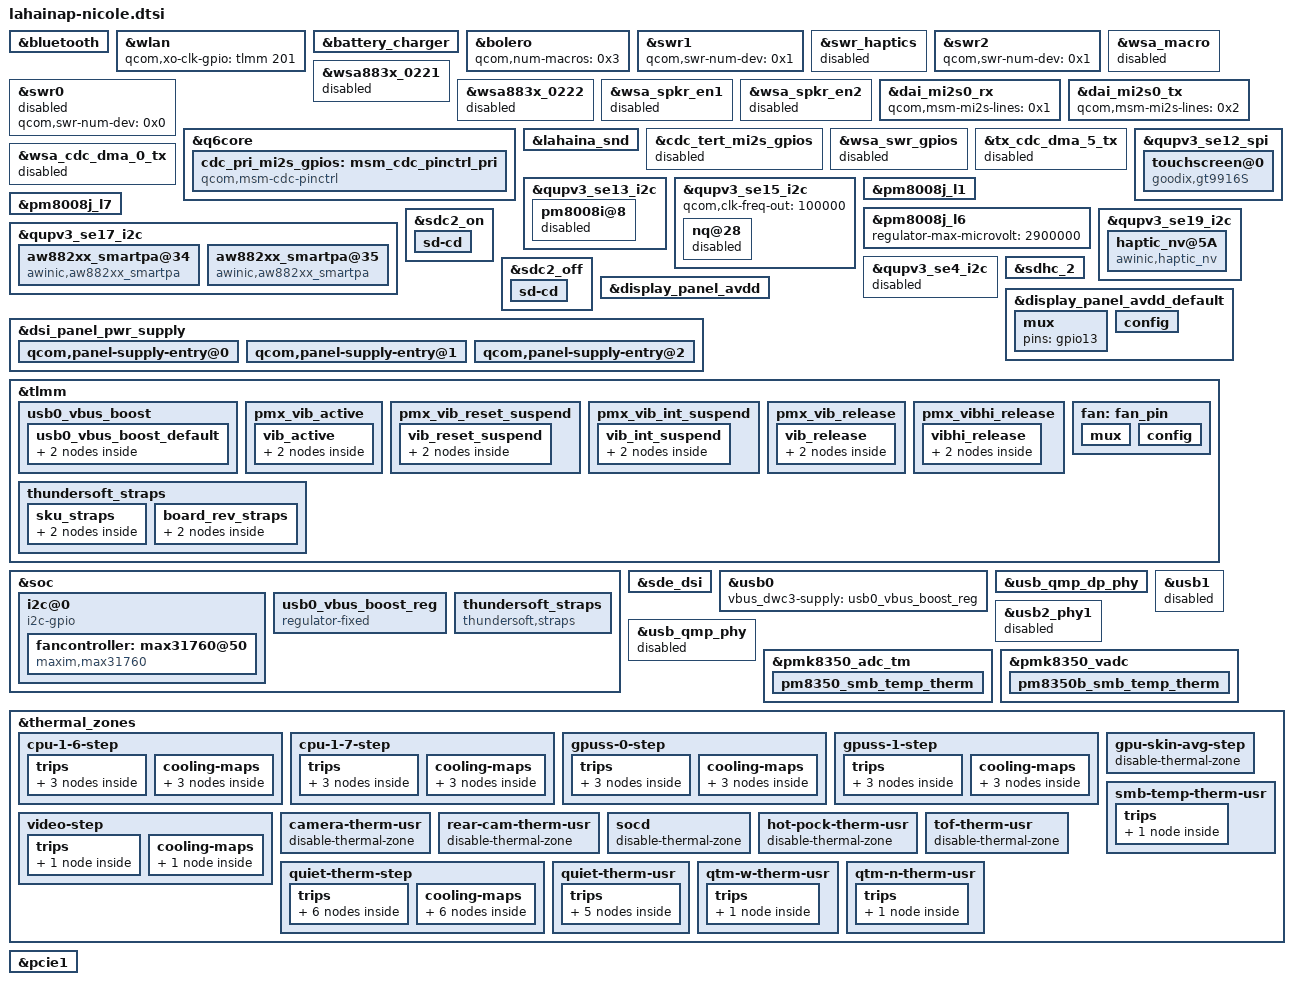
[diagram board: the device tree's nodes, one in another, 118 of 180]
#include <dt-bindings/clock/qcom,gcc-lahaina.h>
#include <dt-bindings/phy/qcom,usb3-5nm-qmp-combo.h>
#include "lahaina-qrd-common.dtsi"
#include "camera/lahaina-camera-sensor-nicole.dtsi"

&bluetooth {
	pinctrl-1 = <&wcnss_en_sleep>;
	qcom,xo-reset-gpio = <&tlmm 201 0>; /* XO */
};

&wlan {
	qcom,xo-clk-gpio = <&tlmm 201 0>;
};

&battery_charger {
	qcom,thermal-mitigation = <5000000 4000000 3000000 2000000 900000>;
};

&bolero {
	qcom,num-macros = <0x3>;
};

&swr1 {
	qcom,swr-num-dev = <0x1>;
};

&swr_haptics {
	status = "disabled";
};

&swr2 {
	qcom,swr-num-dev = <0x1>;
};

&wsa_macro {
	status = "disabled";
};

&swr0 {
	qcom,swr-num-dev = <0x0>;
	status = "disabled";
};

&wsa883x_0221 {
	status = "disabled";
};

&wsa883x_0222 {
	status = "disabled";
};

&wsa_spkr_en1 {
	status = "disabled";
};

&wsa_spkr_en2 {
	status = "disabled";
};

&dai_mi2s0_rx {
	qcom,msm-mi2s-lines = <0x1>;
};

&dai_mi2s0_tx {
	qcom,msm-mi2s-lines = <0x2>;
};

&q6core {
	cdc_pri_mi2s_gpios: msm_cdc_pinctrl_pri {
		compatible = "qcom,msm-cdc-pinctrl";
		pinctrl-names = "aud_active", "aud_sleep";
		pinctrl-0 = <&pri_mi2s_sck_active &pri_mi2s_ws_active
				&pri_mi2s_sd0_active &pri_mi2s_sd1_active>;
		pinctrl-1 = <&pri_mi2s_sck_sleep &pri_mi2s_ws_sleep
				&pri_mi2s_sd0_sleep &pri_mi2s_sd1_sleep>;
		#gpio-cells = <0>;
	};
};

&lahaina_snd {
	qcom,model = "lahaina-hhg-snd-card";

	qcom,audio-routing =
		"AMIC2", "Analog Mic2",
		"Analog Mic2", "MIC BIAS2",
		"TX DMIC1", "Digital Mic1",
		"Digital Mic1", "MIC BIAS1",
		"TX DMIC2", "Digital Mic2",
		"Digital Mic2", "MIC BIAS3",
		"IN1_HPHL", "HPHL_OUT",
		"IN2_HPHR", "HPHR_OUT",
		"IN3_AUX", "AUX_OUT",
		"RX_TX DEC0_INP", "TX DEC0 MUX",
		"RX_TX DEC1_INP", "TX DEC1 MUX",
		"RX_TX DEC2_INP", "TX DEC2 MUX",
		"RX_TX DEC3_INP", "TX DEC3 MUX",
		"TX SWR_INPUT", "WCD_TX_OUTPUT",
		"VA SWR_INPUT", "VA_SWR_CLK",
		"VA SWR_INPUT", "WCD_TX_OUTPUT",
		"VA_AIF1 CAP", "VA_SWR_CLK",
		"VA_AIF2 CAP", "VA_SWR_CLK",
		"VA_AIF3 CAP", "VA_SWR_CLK",
		"VA DMIC1", "Digital Mic1",
		"VA DMIC2", "Digital Mic2",
		"VA DMIC1", "VA MIC BIAS1",
		"VA DMIC2", "VA MIC BIAS2";
	qcom,msm-mbhc-usbc-audio-supported = <1>;
	qcom,msm-mbhc-hphl-swh = <0>;
	qcom,msm-mbhc-gnd-swh = <0>;
	qcom,mi2s-audio-intf = <1>;
	qcom,pri-mi2s-gpios = <&cdc_pri_mi2s_gpios>;
	/delete-property/ qcom,tert-mi2s-gpios;
	asoc-codec  = <&stub_codec>, <&bolero>,
		      <&wcd938x_codec>, <&swr_haptics>,
		      <&swr_dmic_04>, <&swr_dmic_03>,
		      <&swr_dmic_02>, <&swr_dmic_01>,
		      <&ext_disp_audio_codec>;
	asoc-codec-names = "msm-stub-codec.1", "bolero_codec",
			   "wcd938x_codec", "swr-haptics",
			   "swr-dmic.04", "swr-dmic.03",
			   "swr-dmic.02", "swr-dmic.01",
			   "msm-ext-disp-audio-codec-rx";
	qcom,wsa-max-devs = <0>;
};

&cdc_tert_mi2s_gpios {
	status = "disabled";
};

&wsa_swr_gpios {
	status = "disabled";
};

&tx_cdc_dma_5_tx {
	status = "disabled";
};

&wsa_cdc_dma_0_tx {
	status = "disabled";
};

&qupv3_se12_spi {
	status = "ok";

	touchscreen@0 {
		compatible = "goodix,gt9916S", "focaltech,fts";
		reg = <0x0>;
		spi-max-frequency = <6000000>;
		interrupt-parent = <&tlmm>;
		interrupts = <23 0x2008>;
		goodix,reset-gpio = <&tlmm 22 0x00>;
		goodix,irq-gpio = <&tlmm 23 0x2008>;
		goodix,irq-flags = <0x02>;
		goodix,max-touch-number = <5>;
		goodix,panel-max-x = <1080>;
		goodix,panel-max-y = <2400>;
		goodix,panel-max-w = <255>;
		goodix,panel-max-p = <4096>;
		goodix,firmware-name = "goodix_firmware.bin";
		goodix,config-name = "goodix_cfg_group.bin";
		goodix,pen-enable;
		focaltech,reset-gpio = <&tlmm 22 0x00>;
		focaltech,irq-gpio = <&tlmm 23 0x2008>;
		focaltech,max-touch-number = <10>;
		focaltech,display-coords = <0 0 1080 2400>;
		vdd-supply = <&L3C>;
		vcc_i2c-supply = <&L8C>;
		pinctrl-names = "pmx_ts_active", "pmx_ts_suspend", "pmx_ts_release";
		pinctrl-0 = <&ts_active>;
		pinctrl-1 = <&ts_int_suspend &ts_reset_suspend>;
		pinctrl-2 = <&ts_release>;
		panel = <&dsi_vtdr6130_amoled_cmd>;
	};
};

&qupv3_se13_i2c {
	pm8008i@8 {
		status = "disabled";
	};
};

&qupv3_se15_i2c {
	qcom,clk-freq-out = <100000>;
	nq@28 {
		status = "disabled";
	};
};

&pm8008j_l1 {
	regulator-max-microvolt = <1200000>;
	regulator-min-microvolt = <1200000>;
};

&pm8008j_l6 {
	regulator-max-microvolt = <2900000>;
};

&pm8008j_l7 {
	regulator-min-microvolt = <3200000>;
	regulator-max-microvolt = <3300000>;
};

&qupv3_se17_i2c {
	status = "ok";

	aw882xx_smartpa@34 {
		compatible = "awinic,aw882xx_smartpa";
		reg = <0x34>;
		irq-gpio = <&tlmm 90 0x2008>;
		dc-flag = <0>;
		monitor-flag = <1>;
		monitor-timer-val = <3000>;
		aw-tx-port-id = <0x1001>;
		aw-rx-port-id = <0x1000>;
		sound-channel = <0>;
		spin-mode = "dsp_spin";
		status = "okay";
	};

	aw882xx_smartpa@35 {
		compatible = "awinic,aw882xx_smartpa";
		reg = <0x35>;
		irq-gpio = <&tlmm 119 0x2008>;
		dc-flag = <0>;
		monitor-flag = <1>;
		monitor-timer-val = <3000>;
		aw-tx-port-id = <0x1001>;
		aw-rx-port-id = <0x1000>;
		sound-channel = <1>;
		spin-mode = "dsp_spin";
		status = "okay";
	};
};

&qupv3_se19_i2c {
	status = "ok";

	haptic_nv@5A {
		compatible = "awinic,haptic_nv";
		reg = <0x5A>;
		#cooling-cells = <0x2>;
		aw862xx_i2c_addr = <0x58>;
		interrupt-parent = <&tlmm>;
		interrupts = <44 0x2008>;
		reset-gpio = <&tlmm 106 0x0>;
		irq-gpio = <&tlmm 44 0x2008>;
		pinctrl-names = "pmx_vib_active", "pmx_vib_suspend", "pmx_vib_release", "pmx_vibhi_release";
		pinctrl-0 = <&vib_active &vibhi_release>;
		pinctrl-1 = <&vib_int_suspend &vib_reset_suspend>;
		pinctrl-2 = <&vib_release &vib_reset_suspend>;
		aw8622x_vib_lk_f0_cali = <0x0>;
		aw8622x_vib_mode = <0x2>;
		aw8622x_vib_f0_pre = <0x92E>;
		aw8622x_vib_f0_cali_percen = <0x7>;
		aw8622x_vib_cont_drv1_lvl = <0x7F>;
		aw8622x_vib_cont_drv2_lvl = <0x4E>;
		aw8622x_vib_cont_brk_time = <0x6>;
		aw8622x_vib_cont_tset = <0x6>;
		aw8622x_vib_cont_bemf_set = <0x2>;
		aw8622x_vib_cont_drv_width = <0x44>;
		aw8622x_vib_cont_wait_num = <0x6>;
		aw8622x_vib_cont_brk_gain = <0x8>;
		aw8622x_vib_cont_drv1_time = <0x4>;
		aw8622x_vib_cont_drv2_time = <0x14>;
		aw8622x_vib_cont_track_margin = <0x12>;
		aw8622x_vib_sine_array = <0x5 0xB2 0xFF 0xEF>;
		aw8622x_vib_d2s_gain = <0x6>;
		aw8622x_vib_trig_config = <0x0 0x0 0x0 0x1 0x0 0x2 0x0 0x0 0x0 0x0 0x1 0x0 0x2 0x0 0x0 0x0 0x0 0x1 0x0 0x2 0x0>;
		aw8622x_vib_duration_time = <0x14 0x1E 0x3C>;
		status = "okay";
	};
};

&qupv3_se4_i2c {
	status = "disabled";

	/delete-node/ focaltech@38;
};

&sdc2_on {
	sd-cd {
		pins = "gpio80";
		bias-pull-up;
		drive-strength = <2>;
	};
};

&sdc2_off {
	sd-cd {
		pins = "gpio80";
		bias-disable;
		drive-strength = <2>;
	};
};

&sdhc_2 {
	cd-gpios = <&tlmm 80 GPIO_ACTIVE_HIGH>;

	cap-mmc-hw-reset;

	resets = <&clock_gcc GCC_SDCC2_BCR>;
	reset-names = "core_reset";
};

&display_panel_avdd {
	/delete-property/ enable-active-high;
	enable-active-low;
	gpio = <&tlmm 13 0>;
};

&dsi_panel_pwr_supply {
	qcom,panel-supply-entry@0 {
		qcom,supply-min-voltage = <1860000>;
		qcom,supply-max-voltage = <1860000>;
	};

	qcom,panel-supply-entry@1 {
		qcom,supply-pre-off-sleep = <2>;
		qcom,supply-post-off-sleep = <2>;
	};

	qcom,panel-supply-entry@2 {
		qcom,supply-name = "avdd";
		qcom,supply-enable-load = <100000>;
	};

	/delete-node/ qcom,panel-supply-entry@3;
};

&display_panel_avdd_default {
	mux {
		pins = "gpio13";
	};

	config {
		pins = "gpio13";
		/delete-property/ output-high;
		output-low;
	};
};

&tlmm {
	usb0_vbus_boost {
		usb0_vbus_boost_default: usb0_vbus_boost_default {
			mux {
				pins = "gpio79";
				function = "gpio";
			};

			config {
				pins = "gpio79";
				bias-pull-up;
				drive-strength = <6>;
				input-enable;
			};
		};
	};

	pmx_vib_active {
		vib_active: vib_active {
			mux {
				pins = "gpio106", "gpio44";
				function = "gpio";
			};

			config {
				pins = "gpio106", "gpio44";
				drive-strength = <8>;
				bias-pull-up;
			};
		};
	};

	pmx_vib_reset_suspend {
		vib_reset_suspend: vib_reset_suspend {
			mux {
				pins = "gpio106";
				function = "gpio";
			};

			config {
				pins = "gpio106";
				drive-strength = <2>;
				bias-pull-down;
			};
		};
	};

	pmx_vib_int_suspend {
		vib_int_suspend: vib_int_suspend {
			mux {
				pins = "gpio44";
				function = "gpio";
			};

			config {
				pins = "gpio44";
				drive-strength = <2>;
				bias-pull-down;
			};
		};
	};

	pmx_vib_release {
		vib_release: vib_release {
			mux {
				pins = "gpio106", "gpio44";
				function = "gpio";
			};

			config {
				pins = "gpio106", "gpio44";
				drive-strength = <2>;
				bias-disable;
			};
		};
	};

	pmx_vibhi_release {
		vibhi_release: vibhi_release {
			mux {
				pins = "gpio16", "gpio17";
				function = "gpio";
			};

			config {
				pins = "gpio16", "gpio17";
				bias-high-impedance;
			};
		};
	};

	fan: fan_pin {
		mux {
			pins = "gpio8", "gpio9";
			function = "gpio";
		};

		config {
			pins = "gpio8", "gpio9";
			bias-pull-up;
			drive-strength = <16>;
		};
	};

	thundersoft_straps {
		sku_straps: sku_straps {
			mux {
				pins = "gpio3", "gpio6", "gpio7";
				function = "gpio";
			};

			config {
				pins = "gpio3", "gpio6", "gpio7";
				drive-strength = <2>;
				bias-pull-up;
				input-enable;
			};
		};

		board_rev_straps: board_rev_straps {
			mux {
				pins = "gpio45", "gpio50", "gpio51";
				function = "gpio";
			};

			config {
				pins = "gpio45", "gpio50", "gpio51";
				drive-strength = <2>;
				bias-pull-up;
				input-enable;
			};
		};
	};
};

&soc {
	i2c@0 {
		compatible = "i2c-gpio";
		reg = <0x0>;
		pinctrl-names = "default";
		pinctrl-0 = <&fan>;
		gpios = <&tlmm 8 (GPIO_ACTIVE_HIGH | GPIO_OPEN_DRAIN) /* sda */>,
			<&tlmm 9 (GPIO_ACTIVE_HIGH | GPIO_OPEN_DRAIN) /* scl */>;

		i2c-gpio,sda-open-drain;
		i2c-gpio,scl-open-drain;
		i2c-gpio,delay-us = <5>;
		#address-cells = <1>;
		#size-cells = <0>;

		fancontroller: max31760@50 {
			compatible = "maxim,max31760";
			reg = <0x50>;
			#cooling-cells = <2>;
			maxim,vdd-supply = <&pm8008j_l7>;
			regulator-names = "maxim,vdd";
			maxim,vdda-supply = <&pm8008j_l6>;
			maxim,vcca-supply = <&pm8350_s10>;
			maxim,usb_charge_contrl = <&tlmm 78 0>;
			maxim,dpr_contrl = <&tlmm 93 0>;
			pinctrl-names = "qupv3_se19_spi_pins";
			pinctrl-1 = <&qupv3_se19_spi_sleep>;
			status = "ok";
		};
	};

	usb0_vbus_boost_reg: usb0_vbus_boost_reg {
		compatible = "regulator-fixed";
		regulator-name = "usb0_vbus_boost_reg";
		regulator-min-microvolt = <5000000>;
		regulator-max-microvolt = <5000000>;
		enable-active-high;
		gpio = <&tlmm 48 GPIO_ACTIVE_HIGH>;
		interrupt-parent = <&tlmm>;
		interrupts = <79 0x2008>;
		interrupt-names = "ocp";
		pinctrl-names = "default";
		pinctrl-0 = <&usb0_vbus_boost_default>;
	};

	thundersoft_straps {
		compatible = "thundersoft,straps";
		sku-gpios = <&tlmm 3 (GPIO_ACTIVE_HIGH | GPIO_PULL_UP)>,
			<&tlmm 6 (GPIO_ACTIVE_HIGH | GPIO_PULL_UP)>,
			<&tlmm 7 (GPIO_ACTIVE_HIGH | GPIO_PULL_UP)>;
		board_rev-gpios = <&tlmm 45 (GPIO_ACTIVE_HIGH | GPIO_PULL_UP)>,
			<&tlmm 50 (GPIO_ACTIVE_HIGH | GPIO_PULL_UP)>,
			<&tlmm 51 (GPIO_ACTIVE_HIGH | GPIO_PULL_UP)>;
		pinctrl-names = "default";
		pinctrl-0 = <&sku_straps &board_rev_straps>;
		status = "ok";
	};
};

&sde_dsi {
	qcom,dsi-ctrl = <&mdss_dsi0>;
	qcom,dsi-phy = <&mdss_dsi_phy0>;
	qcom,platform-reset-gpio = <&tlmm 24 0x0>;

	qcom,dsi-default-panel = <&dsi_vtdr6130_amoled_cmd>;
};

&usb0 {
	vbus_dwc3-supply = <&usb0_vbus_boost_reg>;
};

&usb_qmp_dp_phy {
	qcom,qmp-phy-init-seq =
		/* <reg_offset, value, delay> */
		<USB3_DP_QSERDES_COM_SSC_EN_CENTER 0x01 0
		USB3_DP_QSERDES_COM_SSC_PER1 0x31 0
		USB3_DP_QSERDES_COM_SSC_PER2 0x01 0
		USB3_DP_QSERDES_COM_SSC_STEP_SIZE1_MODE0 0xDE 0
		USB3_DP_QSERDES_COM_SSC_STEP_SIZE2_MODE0 0x07 0
		USB3_DP_QSERDES_COM_SSC_STEP_SIZE1_MODE1 0xDE 0
		USB3_DP_QSERDES_COM_SSC_STEP_SIZE2_MODE1 0x07 0
		USB3_DP_QSERDES_COM_SYSCLK_BUF_ENABLE 0x0A 0
		USB3_DP_QSERDES_COM_CMN_IPTRIM 0x20 0
		USB3_DP_QSERDES_COM_CP_CTRL_MODE0 0x06 0
		USB3_DP_QSERDES_COM_CP_CTRL_MODE1 0x06 0
		USB3_DP_QSERDES_COM_PLL_RCTRL_MODE0 0x16 0
		USB3_DP_QSERDES_COM_PLL_RCTRL_MODE1 0x16 0
		USB3_DP_QSERDES_COM_PLL_CCTRL_MODE0 0x36 0
		USB3_DP_QSERDES_COM_PLL_CCTRL_MODE1 0x36 0
		USB3_DP_QSERDES_COM_SYSCLK_EN_SEL 0x1A 0
		USB3_DP_QSERDES_COM_LOCK_CMP_EN 0x04 0
		USB3_DP_QSERDES_COM_LOCK_CMP1_MODE0 0x14 0
		USB3_DP_QSERDES_COM_LOCK_CMP2_MODE0 0x34 0
		USB3_DP_QSERDES_COM_LOCK_CMP1_MODE1 0x34 0
		USB3_DP_QSERDES_COM_LOCK_CMP2_MODE1 0x82 0
		USB3_DP_QSERDES_COM_DEC_START_MODE0 0x82 0
		USB3_DP_QSERDES_COM_DEC_START_MODE1 0x82 0
		USB3_DP_QSERDES_COM_DIV_FRAC_START1_MODE0 0xAB 0
		USB3_DP_QSERDES_COM_DIV_FRAC_START2_MODE0 0xEA 0
		USB3_DP_QSERDES_COM_DIV_FRAC_START3_MODE0 0x02 0
		USB3_DP_QSERDES_COM_DIV_FRAC_START1_MODE1 0xAB 0
		USB3_DP_QSERDES_COM_DIV_FRAC_START2_MODE1 0xEA 0
		USB3_DP_QSERDES_COM_DIV_FRAC_START3_MODE1 0x02 0
		USB3_DP_QSERDES_COM_VCO_TUNE_MAP 0x02 0
		USB3_DP_QSERDES_COM_VCO_TUNE1_MODE0 0x24 0
		USB3_DP_QSERDES_COM_VCO_TUNE1_MODE1 0x24 0
		USB3_DP_QSERDES_COM_VCO_TUNE2_MODE1 0x02 0
		USB3_DP_QSERDES_COM_HSCLK_SEL 0x01 0
		USB3_DP_QSERDES_COM_CORECLK_DIV_MODE1 0x08 0
		USB3_DP_QSERDES_COM_BIN_VCOCAL_CMP_CODE1_MODE0 0xCA 0
		USB3_DP_QSERDES_COM_BIN_VCOCAL_CMP_CODE2_MODE0 0x1E 0
		USB3_DP_QSERDES_COM_BIN_VCOCAL_CMP_CODE1_MODE1 0xCA 0
		USB3_DP_QSERDES_COM_BIN_VCOCAL_CMP_CODE2_MODE1 0x1E 0
		USB3_DP_QSERDES_COM_BIN_VCOCAL_HSCLK_SEL 0x11 0
		USB3_DP_QSERDES_TXA_RES_CODE_LANE_TX 0x00 0
		USB3_DP_QSERDES_TXA_RES_CODE_LANE_RX 0x00 0
		USB3_DP_QSERDES_TXA_RES_CODE_LANE_OFFSET_TX 0x16 0
		USB3_DP_QSERDES_TXA_RES_CODE_LANE_OFFSET_RX 0x0E 0
		USB3_DP_QSERDES_TXA_LANE_MODE_1 0x35 0
		USB3_DP_QSERDES_TXA_LANE_MODE_3 0x3F 0
		USB3_DP_QSERDES_TXA_LANE_MODE_4 0x7F 0
		USB3_DP_QSERDES_TXA_LANE_MODE_5 0x3F 0
		USB3_DP_QSERDES_TXA_RCV_DETECT_LVL_2 0x12 0
		USB3_DP_QSERDES_TXA_PI_QEC_CTRL 0x21 0
		USB3_DP_QSERDES_RXA_UCDR_FO_GAIN 0x0A 0
		USB3_DP_QSERDES_RXA_UCDR_SO_GAIN 0x03 0
		USB3_DP_QSERDES_RXA_UCDR_FASTLOCK_FO_GAIN 0x2F 0
		USB3_DP_QSERDES_RXA_UCDR_SO_SATURATION_AND_ENABLE 0x7F 0
		USB3_DP_QSERDES_RXA_UCDR_FASTLOCK_COUNT_LOW 0xFF 0
		USB3_DP_QSERDES_RXA_UCDR_FASTLOCK_COUNT_HIGH 0x0F 0
		USB3_DP_QSERDES_RXA_UCDR_PI_CONTROLS 0x99 0
		USB3_DP_QSERDES_RXA_UCDR_SB2_THRESH1 0x08 0
		USB3_DP_QSERDES_RXA_UCDR_SB2_THRESH2 0x08 0
		USB3_DP_QSERDES_RXA_UCDR_SB2_GAIN1 0x00 0
		USB3_DP_QSERDES_RXA_UCDR_SB2_GAIN2 0x04 0
		USB3_DP_QSERDES_RXA_VGA_CAL_CNTRL1 0x54 0
		USB3_DP_QSERDES_RXA_VGA_CAL_CNTRL2 0x0F 0
		USB3_DP_QSERDES_RXA_RX_EQU_ADAPTOR_CNTRL2 0x0F 0
		USB3_DP_QSERDES_RXA_RX_EQU_ADAPTOR_CNTRL3 0x4A 0
		USB3_DP_QSERDES_RXA_RX_EQU_ADAPTOR_CNTRL4 0x0A 0
		USB3_DP_QSERDES_RXA_RX_IDAC_TSETTLE_LOW 0xC0 0
		USB3_DP_QSERDES_RXA_RX_IDAC_TSETTLE_HIGH 0x00 0
		USB3_DP_QSERDES_RXA_RX_EQ_OFFSET_ADAPTOR_CNTRL1 0x47 0
		USB3_DP_QSERDES_RXA_SIGDET_CNTRL 0x04 0
		USB3_DP_QSERDES_RXA_SIGDET_DEGLITCH_CNTRL 0x0E 0
		USB3_DP_QSERDES_RXA_RX_MODE_00_LOW 0xBB 0
		USB3_DP_QSERDES_RXA_RX_MODE_00_HIGH 0x7B 0
		USB3_DP_QSERDES_RXA_RX_MODE_00_HIGH2 0xBB 0
		USB3_DP_QSERDES_RXA_RX_MODE_00_HIGH3 0x3D 0
		USB3_DP_QSERDES_RXA_RX_MODE_00_HIGH4 0xDB 0
		USB3_DP_QSERDES_RXA_RX_MODE_01_LOW 0x64 0
		USB3_DP_QSERDES_RXA_RX_MODE_01_HIGH 0x24 0
		USB3_DP_QSERDES_RXA_RX_MODE_01_HIGH2 0xD2 0
		USB3_DP_QSERDES_RXA_RX_MODE_01_HIGH3 0x13 0
		USB3_DP_QSERDES_RXA_RX_MODE_01_HIGH4 0xA9 0
		USB3_DP_QSERDES_RXA_DFE_EN_TIMER 0x04 0
		USB3_DP_QSERDES_RXA_DFE_CTLE_POST_CAL_OFFSET 0x38 0
		USB3_DP_QSERDES_RXA_AUX_DATA_TCOARSE_TFINE 0xA0 0
		USB3_DP_QSERDES_RXA_DCC_CTRL1 0x0C 0
		USB3_DP_QSERDES_RXA_GM_CAL 0x00 0
		USB3_DP_QSERDES_RXA_VTH_CODE 0x10 0
		USB3_DP_QSERDES_TXB_RES_CODE_LANE_TX 0x00 0
		USB3_DP_QSERDES_TXB_RES_CODE_LANE_RX 0x00 0
		USB3_DP_QSERDES_TXB_RES_CODE_LANE_OFFSET_TX 0x16 0
		USB3_DP_QSERDES_TXB_RES_CODE_LANE_OFFSET_RX 0x0E 0
		USB3_DP_QSERDES_TXB_LANE_MODE_1 0x35 0
		USB3_DP_QSERDES_TXB_LANE_MODE_3 0x3F 0
		USB3_DP_QSERDES_TXB_LANE_MODE_4 0x7F 0
		USB3_DP_QSERDES_TXB_LANE_MODE_5 0x3F 0
		USB3_DP_QSERDES_TXB_RCV_DETECT_LVL_2 0x12 0
		USB3_DP_QSERDES_TXB_PI_QEC_CTRL 0x21 0
		USB3_DP_QSERDES_RXB_UCDR_SO_GAIN 0x03 0
		USB3_DP_QSERDES_RXB_UCDR_FO_GAIN 0x0A 0
		USB3_DP_QSERDES_RXB_UCDR_FASTLOCK_FO_GAIN 0x2F 0
		USB3_DP_QSERDES_RXB_UCDR_SO_SATURATION_AND_ENABLE 0x7F 0
		USB3_DP_QSERDES_RXB_UCDR_FASTLOCK_COUNT_LOW 0xFF 0
		USB3_DP_QSERDES_RXB_UCDR_FASTLOCK_COUNT_HIGH 0x0F 0
		USB3_DP_QSERDES_RXB_UCDR_PI_CONTROLS 0x99 0
		USB3_DP_QSERDES_RXB_UCDR_SB2_THRESH1 0x08 0
		USB3_DP_QSERDES_RXB_UCDR_SB2_THRESH2 0x08 0
		USB3_DP_QSERDES_RXB_UCDR_SB2_GAIN1 0x00 0
		USB3_DP_QSERDES_RXB_UCDR_SB2_GAIN2 0x04 0
		USB3_DP_QSERDES_RXB_VGA_CAL_CNTRL1 0x54 0
		USB3_DP_QSERDES_RXB_VGA_CAL_CNTRL2 0x0F 0
		USB3_DP_QSERDES_RXB_RX_EQU_ADAPTOR_CNTRL2 0x0F 0
		USB3_DP_QSERDES_RXB_RX_EQU_ADAPTOR_CNTRL3 0x4A 0
		USB3_DP_QSERDES_RXB_RX_EQU_ADAPTOR_CNTRL4 0x0A 0
		USB3_DP_QSERDES_RXB_RX_IDAC_TSETTLE_LOW 0xC0 0
		USB3_DP_QSERDES_RXB_RX_IDAC_TSETTLE_HIGH 0x00 0
		USB3_DP_QSERDES_RXB_RX_EQ_OFFSET_ADAPTOR_CNTRL1 0x47 0
		USB3_DP_QSERDES_RXB_SIGDET_CNTRL 0x04 0
		USB3_DP_QSERDES_RXB_SIGDET_DEGLITCH_CNTRL 0x0E 0
		USB3_DP_QSERDES_RXB_RX_MODE_00_LOW 0xBB 0
		USB3_DP_QSERDES_RXB_RX_MODE_00_HIGH 0x7B 0
		USB3_DP_QSERDES_RXB_RX_MODE_00_HIGH2 0xBB 0
		USB3_DP_QSERDES_RXB_RX_MODE_00_HIGH3 0x3C 0
		USB3_DP_QSERDES_RXB_RX_MODE_00_HIGH4 0xDB 0
		USB3_DP_QSERDES_RXB_RX_MODE_01_LOW 0x64 0
		USB3_DP_QSERDES_RXB_RX_MODE_01_HIGH 0x24 0
		USB3_DP_QSERDES_RXB_RX_MODE_01_HIGH2 0xD2 0
		USB3_DP_QSERDES_RXB_RX_MODE_01_HIGH3 0x13 0
		USB3_DP_QSERDES_RXB_RX_MODE_01_HIGH4 0xA9 0
		USB3_DP_QSERDES_RXB_DFE_EN_TIMER 0x04 0
		USB3_DP_QSERDES_RXB_DFE_CTLE_POST_CAL_OFFSET 0x38 0
		USB3_DP_QSERDES_RXB_AUX_DATA_TCOARSE_TFINE 0xA0 0
		USB3_DP_QSERDES_RXB_DCC_CTRL1 0x0C 0
		USB3_DP_QSERDES_RXB_GM_CAL 0x00 0
		USB3_DP_PCS_USB3_RCVR_DTCT_DLY_U3_L 0x40 0
		USB3_DP_PCS_USB3_RCVR_DTCT_DLY_U3_H 0x00 0
		USB3_DP_PCS_RCVR_DTCT_DLY_P1U2_L 0xE7 0
		USB3_DP_PCS_RCVR_DTCT_DLY_P1U2_H 0x03 0
		USB3_DP_QSERDES_RXB_VTH_CODE 0x10 0
		USB3_DP_PCS_LOCK_DETECT_CONFIG1 0xD0 0
		USB3_DP_PCS_LOCK_DETECT_CONFIG2 0x07 0
		USB3_DP_PCS_LOCK_DETECT_CONFIG3 0x20 0
		USB3_DP_PCS_LOCK_DETECT_CONFIG6 0x13 0
		USB3_DP_PCS_REFGEN_REQ_CONFIG1 0x21 0
		USB3_DP_PCS_RX_SIGDET_LVL 0xAA 0
		USB3_DP_PCS_CDR_RESET_TIME 0x0A 0
		USB3_DP_PCS_ALIGN_DETECT_CONFIG1 0x88 0
		USB3_DP_PCS_ALIGN_DETECT_CONFIG2 0x13 0
		USB3_DP_PCS_PCS_TX_RX_CONFIG 0x0C 0
		USB3_DP_PCS_EQ_CONFIG1 0x4B 0
		USB3_DP_PCS_EQ_CONFIG5 0x10 0
		USB3_DP_PCS_USB3_LFPS_DET_HIGH_COUNT_VAL 0xF8 0
		USB3_DP_PCS_USB3_RXEQTRAINING_DFE_TIME_S2 0x07 0
		USB3_DP_QSERDES_TXA_TX_EMP_POST1_LVL 0x37 0
		USB3_DP_QSERDES_TXA_TX_DRV_LVL 0x3F 0
		USB3_DP_QSERDES_TXB_TX_EMP_POST1_LVL 0x37 0
		USB3_DP_QSERDES_TXB_TX_DRV_LVL 0x3F 0
		0xffffffff 0xffffffff 0x00>;
};

&usb1 {
	status = "disabled";
};

&usb2_phy1 {
	status = "disabled";
};

&usb_qmp_phy {
	status = "disabled";
};

&pmk8350_adc_tm {
	io-channels = <&pmk8350_vadc PM8350_ADC7_AMUX_THM1_100K_PU>,
			<&pmk8350_vadc PM8350_ADC7_AMUX_THM2_100K_PU>,
			<&pmk8350_vadc PM8350B_ADC7_AMUX_THM3_100K_PU>,
			<&pmk8350_vadc PM8350_ADC7_AMUX_THM4_100K_PU>,
			<&pmk8350_vadc PM8350_ADC7_AMUX_THM5_100K_PU>,
			<&pmk8350_vadc PM8350B_ADC7_AMUX_THM4_100K_PU>,
			<&pmk8350_vadc PM8350B_ADC7_GPIO2_100K_PU>,
			<&pmk8350_vadc PMK8350_ADC7_AMUX_THM1_100K_PU>;

	/delete-node/ pm8350_hot_pocket_therm;

	pm8350_smb_temp_therm {
		reg = <PM8350B_ADC7_AMUX_THM3_100K_PU>;
		qcom,ratiometric;
		qcom,hw-settle-time = <200>;
	};
};

&pmk8350_vadc {
	pm8350b_smb_temp_therm {
		reg = <PM8350B_ADC7_AMUX_THM3_100K_PU>;
		label = "pm8350b_smb_temp_therm";
		qcom,ratiometric;
		qcom,hw-settle-time = <200>;
		qcom,pre-scaling = <1 1>;
	};
};

&thermal_zones {
	cpu-1-6-step {
		trips {
			fan_cpu16_config0: fan-cpu16-config0 {
				temperature = <80000>;
				hysteresis = <5000>;
				type = "passive";
			};

			fan_cpu16_config1: fan-cpu16-config1 {
				temperature = <90000>;
				hysteresis = <5000>;
				type = "passive";
			};

			fan_cpu16_config2: fan-cpu16-config2 {
				temperature = <95000>;
				hysteresis = <5000>;
				type = "passive";
			};
		};

		cooling-maps {
			fan_cdev_0 {
				trip = <&fan_cpu16_config0>;
				cooling-device = <&fancontroller 5 5>;
			};

			fan_cdev_1 {
				trip = <&fan_cpu16_config1>;
				cooling-device = <&fancontroller 6 6>;
			};

			fan_cdev_2 {
				trip = <&fan_cpu16_config2>;
				cooling-device = <&fancontroller 7 7>;
			};
		};
	};

	cpu-1-7-step {
		trips {
			fan_cpu17_config0: fan-cpu17-config0 {
				temperature = <80000>;
				hysteresis = <5000>;
				type = "passive";
			};

			fan_cpu17_config1: fan-cpu17-config1 {
				temperature = <90000>;
				hysteresis = <5000>;
				type = "passive";
			};

			fan_cpu17_config2: fan-cpu17-config2 {
				temperature = <95000>;
				hysteresis = <5000>;
				type = "passive";
			};
		};

		cooling-maps {
			fan_cdev_0 {
				trip = <&fan_cpu17_config0>;
				cooling-device = <&fancontroller 5 5>;
			};

			fan_cdev_1 {
				trip = <&fan_cpu17_config1>;
				cooling-device = <&fancontroller 6 6>;
			};

			fan_cdev_2 {
				trip = <&fan_cpu17_config2>;
				cooling-device = <&fancontroller 7 7>;
			};
		};
	};

	gpuss-0-step {
		trips {
			fan_gpuss0_config0: fan-gpuss0-config0 {
				temperature = <85000>;
				hysteresis = <5000>;
				type = "passive";
			};

			fan_gpuss0_config1: fan-gpuss0-config1 {
				temperature = <90000>;
				hysteresis = <5000>;
				type = "passive";
			};

			fan_gpuss0_config2: fan-gpuss0-config2 {
				temperature = <95000>;
				hysteresis = <0>;
				type = "passive";
			};
		};

		cooling-maps {
			fan_cdev_0 {
				trip = <&fan_gpuss0_config0>;
				cooling-device = <&fancontroller 5 5>;
			};

			fan_cdev_1 {
				trip = <&fan_gpuss0_config1>;
				cooling-device = <&fancontroller 6 6>;
			};

			fan_cdev_2 {
				trip = <&fan_gpuss0_config2>;
				cooling-device = <&fancontroller 7 7>;
			};
		};
	};

	gpuss-1-step {
		trips {
			fan_gpuss1_config0: fan-gpuss1-config0 {
				temperature = <85000>;
				hysteresis = <5000>;
				type = "passive";
			};

			fan_gpuss1_config1: fan-gpuss1-config1 {
				temperature = <90000>;
				hysteresis = <5000>;
				type = "passive";
			};

			fan_gpuss1_config2: fan-gpuss1-config2 {
				temperature = <95000>;
				hysteresis = <0>;
				type = "passive";
			};
		};

		cooling-maps {
			fan_cdev_0 {
				trip = <&fan_gpuss1_config0>;
				cooling-device = <&fancontroller 5 5>;
			};

			fan_cdev_1 {
				trip = <&fan_gpuss1_config1>;
				cooling-device = <&fancontroller 6 6>;
			};

			fan_cdev_2 {
				trip = <&fan_gpuss1_config2>;
				cooling-device = <&fancontroller 7 7>;
			};
		};
	};

	video-step {
		polling-delay-passive = <0>;
		polling-delay = <0>;
		thermal-governor = "step_wise";
		thermal-sensors = <&tsens1 6>;
		trips {
			fan_video_config0: fan-video-config0 {
				temperature = <90000>;
				hysteresis = <2000>;
				type = "passive";
			};
		};

		cooling-maps {
			fan_cdev_0 {
				trip = <&fan_video_config0>;
				cooling-device = <&fancontroller 7 7>;
			};
		};
	};

	gpu-skin-avg-step {
		disable-thermal-zone;
	};

	smb-temp-therm-usr {
		polling-delay-passive = <0>;
		polling-delay = <0>;
		thermal-governor = "user_space";
		thermal-sensors = <&pmk8350_adc_tm PM8350B_ADC7_AMUX_THM3_100K_PU>;
		wake-capable-sensor;
		trips {
			active-config0 {
				temperature = <125000>;
				hysteresis = <1000>;
				type = "passive";
			};
		};
	};

	camera-therm-usr {
		disable-thermal-zone;
	};

	rear-cam-therm-usr {
		disable-thermal-zone;
	};

	socd {
		disable-thermal-zone;
	};

	hot-pock-therm-usr {
		disable-thermal-zone;
	};

	tof-therm-usr {
		disable-thermal-zone;
	};

	quiet-therm-step {
		polling-delay-passive = <0>;
		polling-delay = <0>;
		thermal-governor = "step_wise";
		thermal-sensors = <&pmk8350_adc_tm PM8350_ADC7_AMUX_THM2_100K_PU>;
		trips {
			fan_quiet_config0: fan-quiet-config0 {
				temperature = <32000>;
				hysteresis = <2000>;
				type = "passive";
			};

			fan_quiet_config1: fan-quiet-config1 {
				temperature = <34000>;
				hysteresis = <2000>;
				type = "passive";
			};

			fan_quiet_config2: fan-quiet-config2 {
				temperature = <36000>;
				hysteresis = <2000>;
				type = "passive";
			};

			fan_quiet_config3: fan-quiet-config3 {
				temperature = <38000>;
				hysteresis = <2000>;
				type = "passive";
			};

			fan_quiet_config4: fan-quiet-config4 {
				temperature = <40000>;
				hysteresis = <2000>;
				type = "passive";
			};

			fan_quiet_config5: fan-quiet-config5 {
				temperature = <42000>;
				hysteresis = <2000>;
				type = "passive";
			};
		};

		cooling-maps {
			fan_quiet_cdev_0 {
				trip = <&fan_quiet_config0>;
				cooling-device = <&fancontroller 2 2>;
			};

			fan_quiet_cdev_1 {
				trip = <&fan_quiet_config1>;
				cooling-device = <&fancontroller 3 3>;
			};

			fan_quiet_cdev_2 {
				trip = <&fan_quiet_config2>;
				cooling-device = <&fancontroller 4 4>;
			};

			fan_quiet_cdev_3 {
				trip = <&fan_quiet_config3>;
				cooling-device = <&fancontroller 5 5>;
			};

			fan_quiet_cdev_4 {
				trip = <&fan_quiet_config4>;
				cooling-device = <&fancontroller 6 6>;
			};

			fan_quiet_cdev_5 {
				trip = <&fan_quiet_config5>;
				cooling-device = <&fancontroller 7 7>;
			};
		};
	};

	quiet-therm-usr {
		polling-delay-passive = <0>;
		polling-delay = <0>;
		thermal-governor = "user_space";
		thermal-sensors = <&pmk8350_adc_tm PM8350_ADC7_AMUX_THM2_100K_PU>;
		wake-capable-sensor;
		trips {
			active-config0 {
				temperature = <38000>;
				hysteresis = <2000>;
				type = "passive";
			};

			active-config1 {
				temperature = <40000>;
				hysteresis = <2000>;
				type = "passive";
			};

			active-config2 {
				temperature = <42000>;
				hysteresis = <2000>;
				type = "passive";
			};

			active-config3 {
				temperature = <44000>;
				hysteresis = <2000>;
				type = "passive";
			};

			active-config4 {
				temperature = <46000>;
				hysteresis = <2000>;
				type = "passive";
			};
		};
	};

	qtm-w-therm-usr {
		polling-delay-passive = <0>;
		polling-delay = <0>;
		thermal-governor = "user_space";
		thermal-sensors = <&pmk8350_adc_tm PM8350_ADC7_AMUX_THM4_100K_PU>;
		wake-capable-sensor;
		trips {
			active-config0 {
				temperature = <125000>;
				hysteresis = <1000>;
				type = "passive";
			};
		};
	};

	qtm-n-therm-usr {
		polling-delay-passive = <0>;
		polling-delay = <0>;
		thermal-governor = "user_space";
		thermal-sensors = <&pmk8350_adc_tm PM8350_ADC7_AMUX_THM5_100K_PU>;
		wake-capable-sensor;
		trips {
			active-config0 {
				temperature = <125000>;
				hysteresis = <1000>;
				type = "passive";
			};
		};
	};
};

&pcie1 {
	qcom,link-check-max-count = <50>;
	qcom,boot-option = <0x0>;
};
